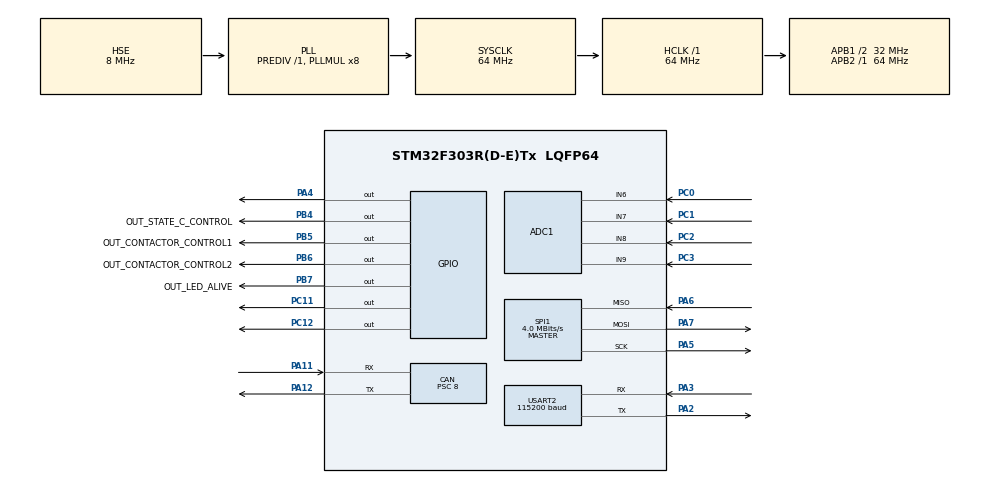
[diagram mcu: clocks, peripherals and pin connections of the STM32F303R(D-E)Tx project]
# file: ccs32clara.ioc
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ADC1.Channel-0\#ChannelRegularConversion=ADC_CHANNEL_6
ADC1.Channel-1\#ChannelRegularConversion=ADC_CHANNEL_7
ADC1.Channel-2\#ChannelRegularConversion=ADC_CHANNEL_8
ADC1.Channel-3\#ChannelRegularConversion=ADC_CHANNEL_9
ADC1.ClockPrescaler=ADC_CLOCK_SYNC_PCLK_DIV4
ADC1.ContinuousConvMode=ENABLE
ADC1.DMAContinuousRequests=ENABLE
ADC1.EOCSelection=ADC_EOC_SEQ_CONV
ADC1.EnableInjectedConversion=DISABLE
ADC1.NbrOfConversion=4
ADC1.NbrOfConversionFlag=1
ADC1.Offset-1\#ChannelRegularConversion=0
ADC1.Offset-2\#ChannelRegularConversion=0
ADC1.Offset-3\#ChannelRegularConversion=0
ADC1.OffsetNumber-1\#ChannelRegularConversion=ADC_OFFSET_NONE
ADC1.OffsetNumber-2\#ChannelRegularConversion=ADC_OFFSET_NONE
ADC1.OffsetNumber-3\#ChannelRegularConversion=ADC_OFFSET_NONE
ADC1.Rank-1\#ChannelRegularConversion=2
ADC1.Rank-2\#ChannelRegularConversion=3
ADC1.Rank-3\#ChannelRegularConversion=4
ADC1.SamplingTime-1\#ChannelRegularConversion=ADC_SAMPLETIME_1CYCLE_5
ADC1.SamplingTime-2\#ChannelRegularConversion=ADC_SAMPLETIME_1CYCLE_5
ADC1.SamplingTime-3\#ChannelRegularConversion=ADC_SAMPLETIME_1CYCLE_5
ADC1.SamplingTimeOPAMP-1\#ChannelRegularConversion=ADC_SAMPLETIME_61CYCLES_5
ADC1.SamplingTimeOPAMP-2\#ChannelRegularConversion=ADC_SAMPLETIME_61CYCLES_5
ADC1.SamplingTimeOPAMP-3\#ChannelRegularConversion=ADC_SAMPLETIME_61CYCLES_5
ADC1.master=1
CAN.BS1=CAN_BS1_6TQ
CAN.CalculateBaudRate=500000
CAN.CalculateTimeBit=2000
CAN.CalculateTimeQuantum=250.0
CAN.NART=ENABLE
CAN.Prescaler=8
Dma.ADC1.0.Direction=DMA_PERIPH_TO_MEMORY
Dma.ADC1.0.Instance=DMA1_Channel1
Dma.ADC1.0.MemDataAlignment=DMA_MDATAALIGN_HALFWORD
Dma.ADC1.0.MemInc=DMA_MINC_ENABLE
Dma.ADC1.0.Mode=DMA_CIRCULAR
Dma.ADC1.0.PeriphDataAlignment=DMA_PDATAALIGN_HALFWORD
Dma.ADC1.0.PeriphInc=DMA_PINC_DISABLE
Dma.ADC1.0.Priority=DMA_PRIORITY_LOW
Dma.Request0=ADC1
Mcu.Family=STM32F3
Mcu.Name=STM32F303R(D-E)Tx
Mcu.Package=LQFP64
NVIC.DMA1_Channel1_IRQn=true\:0\:0\:false\:false\:true\:false\:true\:true
NVIC.PriorityGroup=NVIC_PRIORITYGROUP_4
PA11.Mode=CAN_Activate
PA11.Signal=CAN_RX
PA12.Mode=CAN_Activate
PA12.Signal=CAN_TX
PA13.Mode=Serial_Wire
PA13.Signal=SYS_JTMS-SWDIO
PA14.Mode=Serial_Wire
PA14.Signal=SYS_JTCK-SWCLK
PA2.Mode=Asynchronous
PA2.Signal=USART2_TX
PA3.Mode=Asynchronous
PA3.Signal=USART2_RX
PA4.Signal=GPIO_Output
PA5.Mode=Full_Duplex_Master
PA5.Signal=SPI1_SCK
PA6.Mode=Full_Duplex_Master
PA6.Signal=SPI1_MISO
PA7.Mode=Full_Duplex_Master
PA7.Signal=SPI1_MOSI
PB4.GPIO_Label=OUT_STATE_C_CONTROL
PB4.Signal=GPIO_Output
PB5.GPIO_Label=OUT_CONTACTOR_CONTROL1
PB5.Signal=GPIO_Output
PB6.GPIO_Label=OUT_CONTACTOR_CONTROL2
PB6.Signal=GPIO_Output
PB7.GPIO_Label=OUT_LED_ALIVE
PB7.Signal=GPIO_Output
PC0.Signal=ADCx_IN6
PC1.Signal=ADCx_IN7
PC11.Signal=GPIO_Output
PC12.Signal=GPIO_Output
PC2.Signal=ADCx_IN8
PC3.GPIO_Mode=GPIO_MODE_ANALOG
PC3.GPIO_PuPd=GPIO_NOPULL
PC3.Signal=ADCx_IN9
PF0-OSC_IN.Mode=HSE-External-Oscillator
PF0-OSC_IN.Signal=RCC_OSC_IN
PF1-OSC_OUT.Mode=HSE-External-Oscillator
PF1-OSC_OUT.Signal=RCC_OSC_OUT
ProjectManager.HeapSize=0x200
ProjectManager.StackSize=0x400
ProjectManager.TargetToolchain=STM32CubeIDE
RCC.AHBFreq_Value=64000000
RCC.APB1CLKDivider=RCC_HCLK_DIV2
RCC.APB1Freq_Value=32000000
RCC.APB1TimFreq_Value=64000000
RCC.APB2Freq_Value=64000000
RCC.APB2TimFreq_Value=64000000
RCC.CortexFreq_Value=64000000
RCC.HCLKFreq_Value=64000000
RCC.HSE_VALUE=8000000
RCC.HSI_VALUE=8000000
RCC.LSE_VALUE=32768
RCC.PLLMUL=RCC_PLL_MUL8
RCC.PLLSourceVirtual=RCC_PLLSOURCE_HSE
RCC.SYSCLKFreq_VALUE=64000000
RCC.SYSCLKSourceVirtual=RCC_SYSCLKSOURCE_PLLCLK
RCC.USBFreq_Value=64000000
SH.ADCx_IN6.0=ADC1_IN6,IN6-Single-Ended
SH.ADCx_IN7.0=ADC1_IN7,IN7-Single-Ended
SH.ADCx_IN8.0=ADC1_IN8,IN8-Single-Ended
SH.ADCx_IN9.0=ADC1_IN9,IN9-Single-Ended
SPI1.BaudRatePrescaler=SPI_BAUDRATEPRESCALER_16
SPI1.CLKPhase=SPI_PHASE_2EDGE
SPI1.CLKPolarity=SPI_POLARITY_HIGH
SPI1.CalculateBaudRate=4.0 MBits/s
SPI1.DataSize=SPI_DATASIZE_8BIT
SPI1.Direction=SPI_DIRECTION_2LINES
SPI1.Mode=SPI_MODE_MASTER
SPI1.VirtualType=VM_MASTER
USART2.BaudRate=115200
USART2.VirtualMode-Asynchronous=VM_ASYNC
board=custom

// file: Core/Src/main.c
/* USER CODE BEGIN Header */
/**
 Hints: On the Nucleo F303 board, the user LED LD2 is on PA5, which
 collides with the SPI1_SCK. This means: No LED when SPI is used.

  */
/* USER CODE END Header */
#include "main.h"

/* USER CODE BEGIN Includes */
#include <stdio.h>
#include "ccs32_globals.h"
/* USER CODE END Includes */

ADC_HandleTypeDef hadc1;

CAN_HandleTypeDef hcan;

SPI_HandleTypeDef hspi1;

UART_HandleTypeDef huart2;

/* USER CODE BEGIN PV */
UART_HandleTypeDef huart2;
ADC_ChannelConfTypeDef sConfig = {0};

/* USER CODE END PV */

void SystemClock_Config(void);
static void MX_GPIO_Init(void);
static void MX_ADC1_Init(void);
static void MX_CAN_Init(void);
static void MX_USART2_UART_Init(void);
static void MX_SPI1_Init(void);

/* USER CODE BEGIN 0 */

void mySerialPrint(void) {
  #define TIMEOUT_100_MS 100
  HAL_UART_Transmit(&huart2, (uint8_t*)mySerialPrintOutputBuffer, strlen(mySerialPrintOutputBuffer), TIMEOUT_100_MS);
}

void mySpiTransmitReceive(void) {
  HAL_GPIO_WritePin(GPIOA, GPIO_PIN_4, 0);
  HAL_SPI_TransmitReceive(&hspi1, mySpiTxBuffer, mySpiRxBuffer, mySpiDataSize, 200);
  HAL_GPIO_WritePin(GPIOA, GPIO_PIN_4, 1);
}

/* USER CODE END 0 */

int main(void)
{

  /* MCU Configuration--------------------------------------------------------*/

  /* Reset of all peripherals, Initializes the Flash interface and the Systick. */
  HAL_Init();

  /* Configure the system clock */
  SystemClock_Config();

  /* Initialize all configured peripherals */
  MX_GPIO_Init();
  MX_ADC1_Init();
  MX_CAN_Init();
  MX_USART2_UART_Init();
  MX_SPI1_Init();
  /* USER CODE BEGIN 2 */
  initMyScheduler();
  canbus_Init();
  /* USER CODE END 2 */

  /* Infinite loop */
  while (1)
  {

    /* USER CODE BEGIN 3 */
	runMyScheduler();
  }
  /* USER CODE END 3 */
}

void SystemClock_Config(void)
{
  RCC_OscInitTypeDef RCC_OscInitStruct = {0};
  RCC_ClkInitTypeDef RCC_ClkInitStruct = {0};
  RCC_PeriphCLKInitTypeDef PeriphClkInit = {0};

  /** Initializes the RCC Oscillators according to the specified parameters
  * in the RCC_OscInitTypeDef structure.
  */
  RCC_OscInitStruct.OscillatorType = RCC_OSCILLATORTYPE_HSE;
  RCC_OscInitStruct.HSEState = RCC_HSE_ON;
  RCC_OscInitStruct.HSIState = RCC_HSI_ON;
  RCC_OscInitStruct.PLL.PLLState = RCC_PLL_ON;
  RCC_OscInitStruct.PLL.PLLSource = RCC_PLLSOURCE_HSE;
  RCC_OscInitStruct.PLL.PLLMUL = RCC_PLL_MUL8;
  RCC_OscInitStruct.PLL.PREDIV = RCC_PREDIV_DIV1;
  if (HAL_RCC_OscConfig(&RCC_OscInitStruct) != HAL_OK)
  {
    Error_Handler();
  }

  /** Initializes the CPU, AHB and APB buses clocks
  */
  RCC_ClkInitStruct.ClockType = RCC_CLOCKTYPE_HCLK|RCC_CLOCKTYPE_SYSCLK
                              |RCC_CLOCKTYPE_PCLK1|RCC_CLOCKTYPE_PCLK2;
  RCC_ClkInitStruct.SYSCLKSource = RCC_SYSCLKSOURCE_PLLCLK;
  RCC_ClkInitStruct.AHBCLKDivider = RCC_SYSCLK_DIV1;
  RCC_ClkInitStruct.APB1CLKDivider = RCC_HCLK_DIV2;
  RCC_ClkInitStruct.APB2CLKDivider = RCC_HCLK_DIV1;

  if (HAL_RCC_ClockConfig(&RCC_ClkInitStruct, FLASH_LATENCY_2) != HAL_OK)
  {
    Error_Handler();
  }
  PeriphClkInit.PeriphClockSelection = RCC_PERIPHCLK_USART2;
  PeriphClkInit.Usart2ClockSelection = RCC_USART2CLKSOURCE_PCLK1;
  if (HAL_RCCEx_PeriphCLKConfig(&PeriphClkInit) != HAL_OK)
  {
    Error_Handler();
  }
}

static void MX_ADC1_Init(void)
{

  ADC_MultiModeTypeDef multimode = {0};
  ADC_ChannelConfTypeDef sConfig = {0};

  /** Common config
  */
  hadc1.Instance = ADC1;
  hadc1.Init.ClockPrescaler = ADC_CLOCK_SYNC_PCLK_DIV4;
  hadc1.Init.Resolution = ADC_RESOLUTION_12B;
  hadc1.Init.ScanConvMode = ADC_SCAN_ENABLE;
  hadc1.Init.ContinuousConvMode = ENABLE;
  hadc1.Init.DiscontinuousConvMode = DISABLE;
  hadc1.Init.ExternalTrigConvEdge = ADC_EXTERNALTRIGCONVEDGE_NONE;
  hadc1.Init.ExternalTrigConv = ADC_SOFTWARE_START;
  hadc1.Init.DataAlign = ADC_DATAALIGN_RIGHT;
  hadc1.Init.NbrOfConversion = 5;
  hadc1.Init.DMAContinuousRequests = DISABLE;
  hadc1.Init.EOCSelection = ADC_EOC_SEQ_CONV;
  hadc1.Init.LowPowerAutoWait = DISABLE;
  hadc1.Init.Overrun = ADC_OVR_DATA_OVERWRITTEN;
  if (HAL_ADC_Init(&hadc1) != HAL_OK)
  {
    Error_Handler();
  }

  /** Configure the ADC multi-mode
  */
  multimode.Mode = ADC_MODE_INDEPENDENT;
  if (HAL_ADCEx_MultiModeConfigChannel(&hadc1, &multimode) != HAL_OK)
  {
    Error_Handler();
  }

  /** Configure Regular Channel
  */
  sConfig.Channel = ADC_CHANNEL_6;
  sConfig.Rank = ADC_REGULAR_RANK_1;
  sConfig.SingleDiff = ADC_SINGLE_ENDED;
  sConfig.SamplingTime = ADC_SAMPLETIME_7CYCLES_5;
  sConfig.OffsetNumber = ADC_OFFSET_NONE;
  sConfig.Offset = 0;
  if (HAL_ADC_ConfigChannel(&hadc1, &sConfig) != HAL_OK)
  {
    Error_Handler();
  }

  /** Configure Regular Channel
  */
  sConfig.Channel = ADC_CHANNEL_7;
  sConfig.Rank = ADC_REGULAR_RANK_2;
  if (HAL_ADC_ConfigChannel(&hadc1, &sConfig) != HAL_OK)
  {
    Error_Handler();
  }

  /** Configure Regular Channel
  */
  sConfig.Channel = ADC_CHANNEL_8;
  sConfig.Rank = ADC_REGULAR_RANK_3;
  if (HAL_ADC_ConfigChannel(&hadc1, &sConfig) != HAL_OK)
  {
    Error_Handler();
  }

  /** Configure Regular Channel
  */
  sConfig.Channel = ADC_CHANNEL_9;
  sConfig.Rank = ADC_REGULAR_RANK_4;
  if (HAL_ADC_ConfigChannel(&hadc1, &sConfig) != HAL_OK)
  {
    Error_Handler();
  }

  /** Configure Regular Channel
  */
  sConfig.Channel = ADC_CHANNEL_TEMPSENSOR;
  sConfig.Rank = ADC_REGULAR_RANK_5;
  if (HAL_ADC_ConfigChannel(&hadc1, &sConfig) != HAL_OK)
  {
    Error_Handler();
  }

}

static void MX_CAN_Init(void)
{

  hcan.Instance = CAN;
  hcan.Init.Prescaler = 8;
  hcan.Init.Mode = CAN_MODE_NORMAL;
  hcan.Init.SyncJumpWidth = CAN_SJW_1TQ;
  hcan.Init.TimeSeg1 = CAN_BS1_6TQ;
  hcan.Init.TimeSeg2 = CAN_BS2_1TQ;
  hcan.Init.TimeTriggeredMode = DISABLE;
  hcan.Init.AutoBusOff = DISABLE;
  hcan.Init.AutoWakeUp = DISABLE;
  hcan.Init.AutoRetransmission = ENABLE;
  hcan.Init.ReceiveFifoLocked = DISABLE;
  hcan.Init.TransmitFifoPriority = DISABLE;
  if (HAL_CAN_Init(&hcan) != HAL_OK)
  {
    Error_Handler();
  }

}

static void MX_SPI1_Init(void)
{

  /* SPI1 parameter configuration*/
  hspi1.Instance = SPI1;
  hspi1.Init.Mode = SPI_MODE_MASTER;
  hspi1.Init.Direction = SPI_DIRECTION_2LINES;
  hspi1.Init.DataSize = SPI_DATASIZE_8BIT;
  hspi1.Init.CLKPolarity = SPI_POLARITY_HIGH;
  hspi1.Init.CLKPhase = SPI_PHASE_2EDGE;
  hspi1.Init.NSS = SPI_NSS_SOFT;
  hspi1.Init.BaudRatePrescaler = SPI_BAUDRATEPRESCALER_16;
  hspi1.Init.FirstBit = SPI_FIRSTBIT_MSB;
  hspi1.Init.TIMode = SPI_TIMODE_DISABLE;
  hspi1.Init.CRCCalculation = SPI_CRCCALCULATION_DISABLE;
  hspi1.Init.CRCPolynomial = 7;
  hspi1.Init.CRCLength = SPI_CRC_LENGTH_DATASIZE;
  hspi1.Init.NSSPMode = SPI_NSS_PULSE_DISABLE;
  if (HAL_SPI_Init(&hspi1) != HAL_OK)
  {
    Error_Handler();
  }

}

static void MX_USART2_UART_Init(void)
{

  huart2.Instance = USART2;
  huart2.Init.BaudRate = 115200;
  huart2.Init.WordLength = UART_WORDLENGTH_8B;
  huart2.Init.StopBits = UART_STOPBITS_1;
  huart2.Init.Parity = UART_PARITY_NONE;
  huart2.Init.Mode = UART_MODE_TX_RX;
  huart2.Init.HwFlowCtl = UART_HWCONTROL_NONE;
  huart2.Init.OverSampling = UART_OVERSAMPLING_16;
  huart2.Init.OneBitSampling = UART_ONE_BIT_SAMPLE_DISABLE;
  huart2.AdvancedInit.AdvFeatureInit = UART_ADVFEATURE_NO_INIT;
  if (HAL_UART_Init(&huart2) != HAL_OK)
  {
    Error_Handler();
  }

}

static void MX_GPIO_Init(void)
{
  GPIO_InitTypeDef GPIO_InitStruct = {0};

  /* GPIO Ports Clock Enable */
  __HAL_RCC_GPIOF_CLK_ENABLE();
  __HAL_RCC_GPIOC_CLK_ENABLE();
  __HAL_RCC_GPIOA_CLK_ENABLE();
  __HAL_RCC_GPIOB_CLK_ENABLE();

  /*Configure GPIO pin Output Level */
  HAL_GPIO_WritePin(GPIOA, GPIO_PIN_4, GPIO_PIN_RESET);

  /*Configure GPIO pin Output Level */
  HAL_GPIO_WritePin(GPIOC, GPIO_PIN_11|GPIO_PIN_12, GPIO_PIN_RESET);

  /*Configure GPIO pin Output Level */
  HAL_GPIO_WritePin(GPIOB, OUT_STATE_C_CONTROL_Pin|OUT_CONTACTOR_CONTROL1_Pin|OUT_CONTACTOR_CONTROL2_Pin|OUT_LED_ALIVE_Pin, GPIO_PIN_RESET);

  /*Configure GPIO pin : PA4 */
  GPIO_InitStruct.Pin = GPIO_PIN_4;
  GPIO_InitStruct.Mode = GPIO_MODE_OUTPUT_PP;
  GPIO_InitStruct.Pull = GPIO_NOPULL;
  GPIO_InitStruct.Speed = GPIO_SPEED_FREQ_LOW;
  HAL_GPIO_Init(GPIOA, &GPIO_InitStruct);

  /*Configure GPIO pins : PC11 PC12 */
  GPIO_InitStruct.Pin = GPIO_PIN_11|GPIO_PIN_12;
  GPIO_InitStruct.Mode = GPIO_MODE_OUTPUT_PP;
  GPIO_InitStruct.Pull = GPIO_NOPULL;
  GPIO_InitStruct.Speed = GPIO_SPEED_FREQ_LOW;
  HAL_GPIO_Init(GPIOC, &GPIO_InitStruct);

  /*Configure GPIO pins : OUT_STATE_C_CONTROL_Pin OUT_CONTACTOR_CONTROL1_Pin OUT_CONTACTOR_CONTROL2_Pin OUT_LED_ALIVE_Pin */
  GPIO_InitStruct.Pin = OUT_STATE_C_CONTROL_Pin|OUT_CONTACTOR_CONTROL1_Pin|OUT_CONTACTOR_CONTROL2_Pin|OUT_LED_ALIVE_Pin;
  GPIO_InitStruct.Mode = GPIO_MODE_OUTPUT_PP;
  GPIO_InitStruct.Pull = GPIO_NOPULL;
  GPIO_InitStruct.Speed = GPIO_SPEED_FREQ_LOW;
  HAL_GPIO_Init(GPIOB, &GPIO_InitStruct);

}

void Error_Handler(void)
{
  __disable_irq();
  while (1)
  {
  }
}
